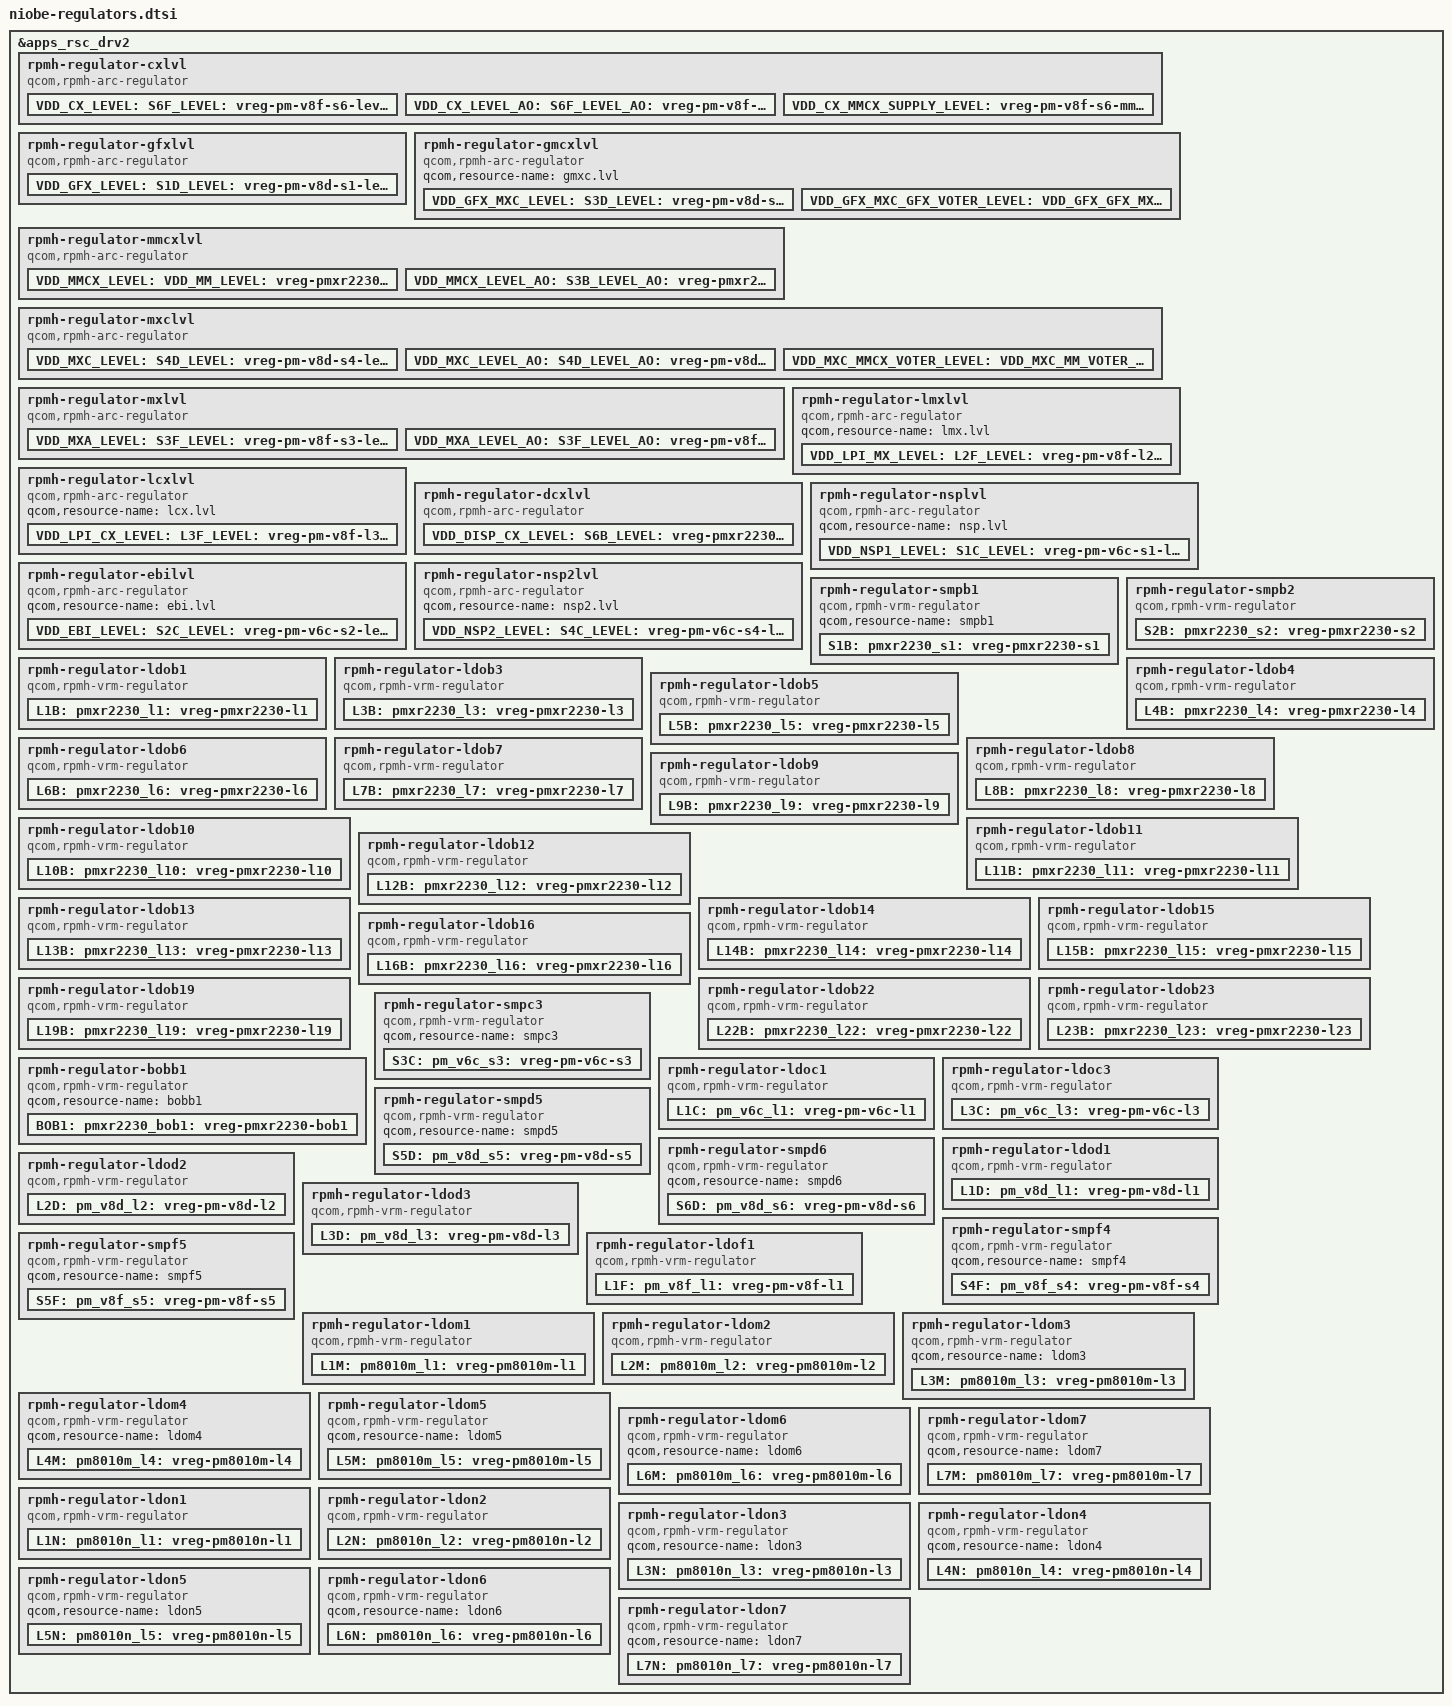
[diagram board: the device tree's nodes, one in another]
#include <dt-bindings/regulator/qcom,rpmh-regulator-levels.h>

&apps_rsc_drv2 {
	rpmh-regulator-cxlvl {
		compatible = "qcom,rpmh-arc-regulator";
		qcom,resource-name = "cx.lvl";
		proxy-supply = <&VDD_CX_LEVEL>;

		VDD_CX_LEVEL:
		S6F_LEVEL:
		pm_v8f_s6_level: vreg-pm-v8f-s6-level {
			regulator-name = "pm_v8f_s6_level";
			qcom,set = <RPMH_REGULATOR_SET_ALL>;
			regulator-min-microvolt =
				<RPMH_REGULATOR_LEVEL_RETENTION>;
			regulator-max-microvolt = <RPMH_REGULATOR_LEVEL_MAX>;
			qcom,init-voltage-level =
				<RPMH_REGULATOR_LEVEL_TURBO>;
			qcom,proxy-consumer-enable;
			qcom,proxy-consumer-voltage =
				<RPMH_REGULATOR_LEVEL_TURBO
				 RPMH_REGULATOR_LEVEL_MAX>;
		};

		VDD_CX_LEVEL_AO:
		S6F_LEVEL_AO:
		pm_v8f_s6_level_ao: vreg-pm-v8f-s6-level-ao {
			regulator-name = "pm_v8f_s6_level_ao";
			qcom,set = <RPMH_REGULATOR_SET_ACTIVE>;
			regulator-min-microvolt =
				<RPMH_REGULATOR_LEVEL_RETENTION>;
			regulator-max-microvolt = <RPMH_REGULATOR_LEVEL_MAX>;
			qcom,init-voltage-level =
				<RPMH_REGULATOR_LEVEL_RETENTION>;
		};

		VDD_CX_MMCX_SUPPLY_LEVEL: vreg-pm-v8f-s6-mmcx-sup-level {
			regulator-name = "pm_v8f_s6_mmcx_sup_level";
			qcom,set = <RPMH_REGULATOR_SET_ALL>;
			regulator-min-microvolt =
				<RPMH_REGULATOR_LEVEL_MIN_SVS>;
			regulator-max-microvolt =
				<RPMH_REGULATOR_LEVEL_MAX>;
			qcom,init-voltage-level =
				<RPMH_REGULATOR_LEVEL_MIN_SVS>;
		};
	};

	rpmh-regulator-gfxlvl {
		compatible = "qcom,rpmh-arc-regulator";
		qcom,resource-name = "gfx.lvl";
		proxy-supply = <&VDD_GFX_LEVEL>;

		VDD_GFX_LEVEL:
		S1D_LEVEL:
		pm_v8d_s1_level: vreg-pm-v8d-s1-level {
			regulator-name = "pm_v8d_s1_level";
			qcom,set = <RPMH_REGULATOR_SET_ALL>;
			regulator-min-microvolt =
				<RPMH_REGULATOR_LEVEL_RETENTION>;
			regulator-max-microvolt = <RPMH_REGULATOR_LEVEL_MAX>;
			qcom,init-voltage-level =
				<RPMH_REGULATOR_LEVEL_RETENTION>;
			qcom,proxy-consumer-enable;
			qcom,proxy-consumer-voltage =
				<RPMH_REGULATOR_LEVEL_LOW_SVS
				 RPMH_REGULATOR_LEVEL_MAX>;
		};
	};

	rpmh-regulator-gmcxlvl {
		compatible = "qcom,rpmh-arc-regulator";
		qcom,resource-name = "gmxc.lvl";

		VDD_GFX_MXC_LEVEL:
		S3D_LEVEL:
		pm_v8d_s3_level: vreg-pm-v8d-s3-level {
			regulator-name = "pm_v8d_s3_level";
			qcom,set = <RPMH_REGULATOR_SET_ALL>;
			regulator-min-microvolt =
				<RPMH_REGULATOR_LEVEL_RETENTION>;
			regulator-max-microvolt = <RPMH_REGULATOR_LEVEL_MAX>;
			qcom,init-voltage-level =
				<RPMH_REGULATOR_LEVEL_RETENTION>;
		};

		VDD_GFX_MXC_GFX_VOTER_LEVEL: VDD_GFX_GFX_MXC_VOTER_LEVEL:
		vreg-pm-v8d-s3-gfx-voter-level {
			regulator-name = "pm_v8d_s3_gfx_voter_level";
			pm_v8d_s3_gfx_voter_level-parent-supply =
				<&VDD_GFX_LEVEL>;
			qcom,set = <RPMH_REGULATOR_SET_ALL>;
			regulator-min-microvolt =
				<RPMH_REGULATOR_LEVEL_MIN_SVS>;
			regulator-max-microvolt =
				<RPMH_REGULATOR_LEVEL_MAX>;
			qcom,init-voltage-level =
				<RPMH_REGULATOR_LEVEL_MIN_SVS>;
		};
	};

	rpmh-regulator-mmcxlvl {
		compatible = "qcom,rpmh-arc-regulator";
		qcom,resource-name = "mmcx.lvl";
		proxy-supply = <&VDD_MMCX_LEVEL>;

		VDD_MMCX_LEVEL:
		VDD_MM_LEVEL:
		S3B_LEVEL:
		pmxr2230_s3_level: vreg-pmxr2230-s3-level {
			regulator-name = "pmxr2230_s3_level";
			qcom,set = <RPMH_REGULATOR_SET_ALL>;
			pmxr2230_s3_level-parent-supply =
				<&VDD_CX_MMCX_SUPPLY_LEVEL>;
			regulator-min-microvolt =
				<RPMH_REGULATOR_LEVEL_LOW_SVS_D1>;
			regulator-max-microvolt = <RPMH_REGULATOR_LEVEL_MAX>;
			qcom,init-voltage-level =
				<RPMH_REGULATOR_LEVEL_TURBO>;
			qcom,proxy-consumer-enable;
			qcom,proxy-consumer-voltage =
				<RPMH_REGULATOR_LEVEL_TURBO
				 RPMH_REGULATOR_LEVEL_MAX>;
		};

		VDD_MMCX_LEVEL_AO:
		S3B_LEVEL_AO:
		pmxr2230_s3_level_ao: vreg-pmxr2230-s3-level-ao {
			regulator-name = "pmxr2230_s3_level_ao";
			qcom,set = <RPMH_REGULATOR_SET_ACTIVE>;
			regulator-min-microvolt =
				<RPMH_REGULATOR_LEVEL_LOW_SVS_D1>;
			regulator-max-microvolt = <RPMH_REGULATOR_LEVEL_MAX>;
			qcom,init-voltage-level =
				<RPMH_REGULATOR_LEVEL_LOW_SVS_D1>;
		};
	};

	rpmh-regulator-mxclvl {
		compatible = "qcom,rpmh-arc-regulator";
		qcom,resource-name = "mxc.lvl";
		proxy-supply = <&VDD_MXC_LEVEL>;

		VDD_MXC_LEVEL:
		S4D_LEVEL:
		pm_v8d_s4_level: vreg-pm-v8d-s4-level {
			regulator-name = "pm_v8d_s4_level";
			qcom,set = <RPMH_REGULATOR_SET_ALL>;
			regulator-min-microvolt =
				<RPMH_REGULATOR_LEVEL_RETENTION>;
			regulator-max-microvolt = <RPMH_REGULATOR_LEVEL_MAX>;
			qcom,init-voltage-level =
				<RPMH_REGULATOR_LEVEL_TURBO>;
			qcom,proxy-consumer-enable;
			qcom,proxy-consumer-voltage =
				<RPMH_REGULATOR_LEVEL_TURBO
				 RPMH_REGULATOR_LEVEL_MAX>;
		};

		VDD_MXC_LEVEL_AO:
		S4D_LEVEL_AO:
		pm_v8d_s4_level_ao: vreg-pm-v8d-s4-level-ao {
			regulator-name = "pm_v8d_s4_level_ao";
			qcom,set = <RPMH_REGULATOR_SET_ACTIVE>;
			regulator-min-microvolt =
				<RPMH_REGULATOR_LEVEL_RETENTION>;
			regulator-max-microvolt = <RPMH_REGULATOR_LEVEL_MAX>;
			qcom,init-voltage-level =
				<RPMH_REGULATOR_LEVEL_RETENTION>;
		};

		VDD_MXC_MMCX_VOTER_LEVEL: VDD_MXC_MM_VOTER_LEVEL:
		VDD_MM_MXC_VOTER_LEVEL:
		vreg-pm-v8d-s4-mmcx-voter-level {
			regulator-name = "pm_v8d_s4_mmcx_voter_level";
			pm_v8d_s4_mmcx_voter_level-parent-supply =
				<&VDD_MMCX_LEVEL>;
			qcom,set = <RPMH_REGULATOR_SET_ALL>;
			regulator-min-microvolt =
				<RPMH_REGULATOR_LEVEL_MIN_SVS>;
			regulator-max-microvolt =
				<RPMH_REGULATOR_LEVEL_MAX>;
			qcom,init-voltage-level =
				<RPMH_REGULATOR_LEVEL_MIN_SVS>;
		};
	};

	rpmh-regulator-mxlvl {
		compatible = "qcom,rpmh-arc-regulator";
		qcom,resource-name = "mx.lvl";
		proxy-supply = <&VDD_MXA_LEVEL>;

		VDD_MXA_LEVEL:
		S3F_LEVEL:
		pm_v8f_s3_level: vreg-pm-v8f-s3-level {
			regulator-name = "pm_v8f_s3_level";
			qcom,set = <RPMH_REGULATOR_SET_ALL>;
			regulator-min-microvolt =
				<RPMH_REGULATOR_LEVEL_RETENTION>;
			regulator-max-microvolt = <RPMH_REGULATOR_LEVEL_MAX>;
			qcom,init-voltage-level =
				<RPMH_REGULATOR_LEVEL_TURBO>;
			qcom,proxy-consumer-enable;
			qcom,proxy-consumer-voltage =
				<RPMH_REGULATOR_LEVEL_TURBO
				 RPMH_REGULATOR_LEVEL_MAX>;
		};

		VDD_MXA_LEVEL_AO:
		S3F_LEVEL_AO:
		pm_v8f_s3_level_ao: vreg-pm-v8f-s3-level-ao {
			regulator-name = "pm_v8f_s3_level_ao";
			qcom,set = <RPMH_REGULATOR_SET_ACTIVE>;
			regulator-min-microvolt =
				<RPMH_REGULATOR_LEVEL_RETENTION>;
			regulator-max-microvolt = <RPMH_REGULATOR_LEVEL_MAX>;
			qcom,init-voltage-level =
				<RPMH_REGULATOR_LEVEL_RETENTION>;
		};
	};

	rpmh-regulator-lmxlvl {
		compatible = "qcom,rpmh-arc-regulator";
		qcom,resource-name = "lmx.lvl";

		VDD_LPI_MX_LEVEL:
		L2F_LEVEL:
		pm_v8f_l2_level: vreg-pm-v8f-l2-level {
			regulator-name = "pm_v8f_l2_level";
			qcom,set = <RPMH_REGULATOR_SET_ALL>;
			regulator-min-microvolt =
				<RPMH_REGULATOR_LEVEL_RETENTION>;
			regulator-max-microvolt = <RPMH_REGULATOR_LEVEL_MAX>;
			qcom,init-voltage-level =
				<RPMH_REGULATOR_LEVEL_RETENTION>;
		};
	};

	rpmh-regulator-lcxlvl {
		compatible = "qcom,rpmh-arc-regulator";
		qcom,resource-name = "lcx.lvl";

		VDD_LPI_CX_LEVEL:
		L3F_LEVEL:
		pm_v8f_l3_level: vreg-pm-v8f-l3-level {
			regulator-name = "pm_v8f_l3_level";
			qcom,set = <RPMH_REGULATOR_SET_ALL>;
			regulator-min-microvolt =
				<RPMH_REGULATOR_LEVEL_RETENTION>;
			regulator-max-microvolt = <RPMH_REGULATOR_LEVEL_MAX>;
			qcom,init-voltage-level =
				<RPMH_REGULATOR_LEVEL_RETENTION>;
		};
	};

	rpmh-regulator-dcxlvl {
		compatible = "qcom,rpmh-arc-regulator";
		qcom,resource-name = "dcx.lvl";
		proxy-supply = <&VDD_DISP_CX_LEVEL>;

		VDD_DISP_CX_LEVEL:
		S6B_LEVEL:
		pmxr2230_s6_level: vreg-pmxr2230-s6-level {
			regulator-name = "pmxr2230_s6_level";
			qcom,set = <RPMH_REGULATOR_SET_ALL>;
			regulator-min-microvolt =
				<RPMH_REGULATOR_LEVEL_LOW_SVS_D1>;
			regulator-max-microvolt = <RPMH_REGULATOR_LEVEL_MAX>;
			qcom,init-voltage-level =
				<RPMH_REGULATOR_LEVEL_LOW_SVS_D1>;
			qcom,proxy-consumer-enable;
			qcom,proxy-consumer-voltage =
				<RPMH_REGULATOR_LEVEL_TURBO
				 RPMH_REGULATOR_LEVEL_MAX>;
		};
	};

	rpmh-regulator-nsplvl {
		compatible = "qcom,rpmh-arc-regulator";
		qcom,resource-name = "nsp.lvl";

		VDD_NSP1_LEVEL:
		S1C_LEVEL:
		pm_v6c_s1_level: vreg-pm-v6c-s1-level {
			regulator-name = "pm_v6c_s1_level";
			qcom,set = <RPMH_REGULATOR_SET_ALL>;
			regulator-min-microvolt =
				<RPMH_REGULATOR_LEVEL_RETENTION>;
			regulator-max-microvolt = <RPMH_REGULATOR_LEVEL_MAX>;
			qcom,init-voltage-level =
				<RPMH_REGULATOR_LEVEL_RETENTION>;
		};
	};

	rpmh-regulator-ebilvl {
		compatible = "qcom,rpmh-arc-regulator";
		qcom,resource-name = "ebi.lvl";

		VDD_EBI_LEVEL:
		S2C_LEVEL:
		pm_v6c_s2_level: vreg-pm-v6c-s2-level {
			regulator-name = "pm_v6c_s2_level";
			qcom,set = <RPMH_REGULATOR_SET_ALL>;
			regulator-min-microvolt =
				<RPMH_REGULATOR_LEVEL_RETENTION>;
			regulator-max-microvolt = <RPMH_REGULATOR_LEVEL_MAX>;
			qcom,init-voltage-level =
				<RPMH_REGULATOR_LEVEL_RETENTION>;
		};
	};

	rpmh-regulator-nsp2lvl {
		compatible = "qcom,rpmh-arc-regulator";
		qcom,resource-name = "nsp2.lvl";

		VDD_NSP2_LEVEL:
		S4C_LEVEL:
		pm_v6c_s4_level: vreg-pm-v6c-s4-level {
			regulator-name = "pm_v6c_s4_level";
			qcom,set = <RPMH_REGULATOR_SET_ALL>;
			regulator-min-microvolt =
				<RPMH_REGULATOR_LEVEL_RETENTION>;
			regulator-max-microvolt = <RPMH_REGULATOR_LEVEL_MAX>;
			qcom,init-voltage-level =
				<RPMH_REGULATOR_LEVEL_RETENTION>;
		};
	};

	rpmh-regulator-smpb1 {
		compatible = "qcom,rpmh-vrm-regulator";
		qcom,resource-name = "smpb1";

		S1B:
		pmxr2230_s1: vreg-pmxr2230-s1 {
			regulator-name = "pmxr2230_s1";
			qcom,set = <RPMH_REGULATOR_SET_ALL>;
			regulator-min-microvolt = <1856000>;
			regulator-max-microvolt = <2040000>;
			qcom,init-voltage = <1856000>;
		};
	};

	rpmh-regulator-smpb2 {
		compatible = "qcom,rpmh-vrm-regulator";
		qcom,resource-name = "smpb2";
		qcom,regulator-type = "pmic5-ftsmps";
		qcom,supported-modes =
			<RPMH_REGULATOR_MODE_RET
			RPMH_REGULATOR_MODE_HPM>;
		qcom,mode-threshold-currents = <0 200000>;

		S2B:
		pmxr2230_s2: vreg-pmxr2230-s2 {
			regulator-name = "pmxr2230_s2";
			qcom,set = <RPMH_REGULATOR_SET_ALL>;
			regulator-min-microvolt = <1216000>;
			regulator-max-microvolt = <1408000>;
			qcom,init-voltage = <1256000>;
			qcom,init-mode = <RPMH_REGULATOR_MODE_RET>;
		};
	};

	rpmh-regulator-ldob1 {
		compatible = "qcom,rpmh-vrm-regulator";
		qcom,resource-name = "ldob1";
		qcom,regulator-type = "pmic5-ldo";
		qcom,supported-modes =
			<RPMH_REGULATOR_MODE_LPM
			RPMH_REGULATOR_MODE_HPM>;
		qcom,mode-threshold-currents = <0 30000>;

		L1B:
		pmxr2230_l1: vreg-pmxr2230-l1 {
			regulator-name = "pmxr2230_l1";
			qcom,set = <RPMH_REGULATOR_SET_ALL>;
			regulator-min-microvolt = <880000>;
			regulator-max-microvolt = <912000>;
			qcom,init-voltage = <880000>;
			qcom,init-mode = <RPMH_REGULATOR_MODE_HPM>;
		};
	};

	rpmh-regulator-ldob3 {
		compatible = "qcom,rpmh-vrm-regulator";
		qcom,resource-name = "ldob3";
		qcom,regulator-type = "pmic5-ldo";
		qcom,supported-modes =
			<RPMH_REGULATOR_MODE_RET
			RPMH_REGULATOR_MODE_LPM
			RPMH_REGULATOR_MODE_HPM>;
		qcom,mode-threshold-currents = <0 10000 30000>;

		L3B:
		pmxr2230_l3: vreg-pmxr2230-l3 {
			regulator-name = "pmxr2230_l3";
			qcom,set = <RPMH_REGULATOR_SET_ALL>;
			regulator-min-microvolt = <1200000>;
			regulator-max-microvolt = <1200000>;
			qcom,init-voltage = <1200000>;
			qcom,init-mode = <RPMH_REGULATOR_MODE_HPM>;
		};
	};

	rpmh-regulator-ldob4 {
		compatible = "qcom,rpmh-vrm-regulator";
		qcom,resource-name = "ldob4";
		qcom,regulator-type = "pmic5-ldo";
		qcom,supported-modes =
			<RPMH_REGULATOR_MODE_LPM
			RPMH_REGULATOR_MODE_HPM>;
		qcom,mode-threshold-currents = <0 30000>;

		L4B:
		pmxr2230_l4: vreg-pmxr2230-l4 {
			regulator-name = "pmxr2230_l4";
			qcom,set = <RPMH_REGULATOR_SET_ALL>;
			regulator-min-microvolt = <1800000>;
			regulator-max-microvolt = <1800000>;
			qcom,init-voltage = <1800000>;
			qcom,init-mode = <RPMH_REGULATOR_MODE_HPM>;
		};
	};

	rpmh-regulator-ldob5 {
		compatible = "qcom,rpmh-vrm-regulator";
		qcom,resource-name = "ldob5";
		qcom,regulator-type = "pmic5-ldo";
		qcom,supported-modes =
			<RPMH_REGULATOR_MODE_LPM
			RPMH_REGULATOR_MODE_HPM>;
		qcom,mode-threshold-currents = <0 30000>;

		L5B:
		pmxr2230_l5: vreg-pmxr2230-l5 {
			regulator-name = "pmxr2230_l5";
			qcom,set = <RPMH_REGULATOR_SET_ALL>;
			regulator-min-microvolt = <1800000>;
			regulator-max-microvolt = <1800000>;
			qcom,init-voltage = <1800000>;
			qcom,init-mode = <RPMH_REGULATOR_MODE_HPM>;
		};
	};

	rpmh-regulator-ldob6 {
		compatible = "qcom,rpmh-vrm-regulator";
		qcom,resource-name = "ldob6";
		qcom,regulator-type = "pmic5-ldo";
		qcom,supported-modes =
			<RPMH_REGULATOR_MODE_LPM
			RPMH_REGULATOR_MODE_HPM>;
		qcom,mode-threshold-currents = <0 30000>;

		L6B:
		pmxr2230_l6: vreg-pmxr2230-l6 {
			regulator-name = "pmxr2230_l6";
			qcom,set = <RPMH_REGULATOR_SET_ALL>;
			regulator-min-microvolt = <1800000>;
			regulator-max-microvolt = <1800000>;
			qcom,init-voltage = <1800000>;
			qcom,init-mode = <RPMH_REGULATOR_MODE_HPM>;
		};
	};

	rpmh-regulator-ldob7 {
		compatible = "qcom,rpmh-vrm-regulator";
		qcom,resource-name = "ldob7";
		qcom,regulator-type = "pmic5-ldo";
		qcom,supported-modes =
			<RPMH_REGULATOR_MODE_LPM
			RPMH_REGULATOR_MODE_HPM>;
		qcom,mode-threshold-currents = <0 30000>;

		L7B:
		pmxr2230_l7: vreg-pmxr2230-l7 {
			regulator-name = "pmxr2230_l7";
			qcom,set = <RPMH_REGULATOR_SET_ALL>;
			regulator-min-microvolt = <1800000>;
			regulator-max-microvolt = <1800000>;
			qcom,init-voltage = <1800000>;
			qcom,init-mode = <RPMH_REGULATOR_MODE_HPM>;
		};
	};

	rpmh-regulator-ldob8 {
		compatible = "qcom,rpmh-vrm-regulator";
		qcom,resource-name = "ldob8";
		qcom,regulator-type = "pmic5-ldo";
		qcom,supported-modes =
			<RPMH_REGULATOR_MODE_LPM
			RPMH_REGULATOR_MODE_HPM>;
		qcom,mode-threshold-currents = <0 30000>;

		L8B:
		pmxr2230_l8: vreg-pmxr2230-l8 {
			regulator-name = "pmxr2230_l8";
			qcom,set = <RPMH_REGULATOR_SET_ALL>;
			regulator-min-microvolt = <880000>;
			regulator-max-microvolt = <880000>;
			qcom,init-voltage = <880000>;
			qcom,init-mode = <RPMH_REGULATOR_MODE_HPM>;
		};
	};

	rpmh-regulator-ldob9 {
		compatible = "qcom,rpmh-vrm-regulator";
		qcom,resource-name = "ldob9";
		qcom,regulator-type = "pmic5-ldo";
		qcom,supported-modes =
			<RPMH_REGULATOR_MODE_LPM
			RPMH_REGULATOR_MODE_HPM>;
		qcom,mode-threshold-currents = <0 30000>;

		L9B:
		pmxr2230_l9: vreg-pmxr2230-l9 {
			regulator-name = "pmxr2230_l9";
			qcom,set = <RPMH_REGULATOR_SET_ALL>;
			regulator-min-microvolt = <880000>;
			regulator-max-microvolt = <880000>;
			qcom,init-voltage = <880000>;
			qcom,init-mode = <RPMH_REGULATOR_MODE_HPM>;
		};
	};

	rpmh-regulator-ldob10 {
		compatible = "qcom,rpmh-vrm-regulator";
		qcom,resource-name = "ldob10";
		qcom,regulator-type = "pmic5-ldo";
		qcom,supported-modes =
			<RPMH_REGULATOR_MODE_LPM
			RPMH_REGULATOR_MODE_HPM>;
		qcom,mode-threshold-currents = <0 30000>;

		L10B:
		pmxr2230_l10: vreg-pmxr2230-l10 {
			regulator-name = "pmxr2230_l10";
			qcom,set = <RPMH_REGULATOR_SET_ALL>;
			regulator-min-microvolt = <880000>;
			regulator-max-microvolt = <880000>;
			qcom,init-voltage = <880000>;
			qcom,init-mode = <RPMH_REGULATOR_MODE_HPM>;
		};
	};

	rpmh-regulator-ldob11 {
		compatible = "qcom,rpmh-vrm-regulator";
		qcom,resource-name = "ldob11";
		qcom,regulator-type = "pmic5-ldo";
		qcom,supported-modes =
			<RPMH_REGULATOR_MODE_LPM
			RPMH_REGULATOR_MODE_HPM>;
		qcom,mode-threshold-currents = <0 30000>;

		L11B:
		pmxr2230_l11: vreg-pmxr2230-l11 {
			regulator-name = "pmxr2230_l11";
			qcom,set = <RPMH_REGULATOR_SET_ALL>;
			regulator-min-microvolt = <1800000>;
			regulator-max-microvolt = <1800000>;
			qcom,init-voltage = <1800000>;
			qcom,init-mode = <RPMH_REGULATOR_MODE_HPM>;
		};
	};

	rpmh-regulator-ldob12 {
		compatible = "qcom,rpmh-vrm-regulator";
		qcom,resource-name = "ldob12";
		qcom,regulator-type = "pmic5-ldo";
		qcom,supported-modes =
			<RPMH_REGULATOR_MODE_LPM
			RPMH_REGULATOR_MODE_HPM>;
		qcom,mode-threshold-currents = <0 10000>;

		L12B:
		pmxr2230_l12: vreg-pmxr2230-l12 {
			regulator-name = "pmxr2230_l12";
			qcom,set = <RPMH_REGULATOR_SET_ALL>;
			regulator-min-microvolt = <2700000>;
			regulator-max-microvolt = <3304000>;
			qcom,init-voltage = <2700000>;
			qcom,init-mode = <RPMH_REGULATOR_MODE_HPM>;
		};
	};

	rpmh-regulator-ldob13 {
		compatible = "qcom,rpmh-vrm-regulator";
		qcom,resource-name = "ldob13";
		qcom,regulator-type = "pmic5-ldo";
		qcom,supported-modes =
			<RPMH_REGULATOR_MODE_LPM
			RPMH_REGULATOR_MODE_HPM>;
		qcom,mode-threshold-currents = <0 10000>;

		L13B:
		pmxr2230_l13: vreg-pmxr2230-l13 {
			regulator-name = "pmxr2230_l13";
			qcom,set = <RPMH_REGULATOR_SET_ALL>;
			regulator-min-microvolt = <2504000>;
			regulator-max-microvolt = <2800000>;
			qcom,init-voltage = <2504000>;
			qcom,init-mode = <RPMH_REGULATOR_MODE_HPM>;
		};
	};

	rpmh-regulator-ldob14 {
		compatible = "qcom,rpmh-vrm-regulator";
		qcom,resource-name = "ldob14";
		qcom,regulator-type = "pmic5-ldo";
		qcom,supported-modes =
			<RPMH_REGULATOR_MODE_LPM
			RPMH_REGULATOR_MODE_HPM>;
		qcom,mode-threshold-currents = <0 10000>;

		L14B:
		pmxr2230_l14: vreg-pmxr2230-l14 {
			regulator-name = "pmxr2230_l14";
			qcom,set = <RPMH_REGULATOR_SET_ALL>;
			regulator-min-microvolt = <2504000>;
			regulator-max-microvolt = <3304000>;
			qcom,init-voltage = <2504000>;
			qcom,init-mode = <RPMH_REGULATOR_MODE_HPM>;
		};
	};

	rpmh-regulator-ldob15 {
		compatible = "qcom,rpmh-vrm-regulator";
		qcom,resource-name = "ldob15";
		qcom,regulator-type = "pmic5-ldo";
		qcom,supported-modes =
			<RPMH_REGULATOR_MODE_LPM
			RPMH_REGULATOR_MODE_HPM>;
		qcom,mode-threshold-currents = <0 10000>;

		L15B:
		pmxr2230_l15: vreg-pmxr2230-l15 {
			regulator-name = "pmxr2230_l15";
			qcom,set = <RPMH_REGULATOR_SET_ALL>;
			regulator-min-microvolt = <2700000>;
			regulator-max-microvolt = <3304000>;
			qcom,init-voltage = <3104000>;
			qcom,init-mode = <RPMH_REGULATOR_MODE_HPM>;
		};
	};

	rpmh-regulator-ldob16 {
		compatible = "qcom,rpmh-vrm-regulator";
		qcom,resource-name = "ldob16";
		qcom,regulator-type = "pmic5-ldo";
		qcom,supported-modes =
			<RPMH_REGULATOR_MODE_LPM
			RPMH_REGULATOR_MODE_HPM>;
		qcom,mode-threshold-currents = <0 10000>;

		L16B:
		pmxr2230_l16: vreg-pmxr2230-l16 {
			regulator-name = "pmxr2230_l16";
			qcom,set = <RPMH_REGULATOR_SET_ALL>;
			regulator-min-microvolt = <3304000>;
			regulator-max-microvolt = <3304000>;
			qcom,init-voltage = <3304000>;
			qcom,init-mode = <RPMH_REGULATOR_MODE_HPM>;
		};
	};

	rpmh-regulator-ldob19 {
		compatible = "qcom,rpmh-vrm-regulator";
		qcom,resource-name = "ldob19";
		qcom,regulator-type = "pmic5-ldo";
		qcom,supported-modes =
			<RPMH_REGULATOR_MODE_LPM
			RPMH_REGULATOR_MODE_HPM>;
		qcom,mode-threshold-currents = <0 10000>;

		L19B:
		pmxr2230_l19: vreg-pmxr2230-l19 {
			regulator-name = "pmxr2230_l19";
			qcom,set = <RPMH_REGULATOR_SET_ALL>;
			regulator-min-microvolt = <1800000>;
			regulator-max-microvolt = <3304000>;
			qcom,init-voltage = <1800000>;
			qcom,init-mode = <RPMH_REGULATOR_MODE_HPM>;
		};
	};

	rpmh-regulator-ldob22 {
		compatible = "qcom,rpmh-vrm-regulator";
		qcom,resource-name = "ldob22";
		qcom,regulator-type = "pmic5-ldo";
		qcom,supported-modes =
			<RPMH_REGULATOR_MODE_LPM
			RPMH_REGULATOR_MODE_HPM>;
		qcom,mode-threshold-currents = <0 10000>;

		L22B:
		pmxr2230_l22: vreg-pmxr2230-l22 {
			regulator-name = "pmxr2230_l22";
			qcom,set = <RPMH_REGULATOR_SET_ALL>;
			regulator-min-microvolt = <2800000>;
			regulator-max-microvolt = <2800000>;
			qcom,init-voltage = <2800000>;
			qcom,init-mode = <RPMH_REGULATOR_MODE_HPM>;
		};
	};

	rpmh-regulator-ldob23 {
		compatible = "qcom,rpmh-vrm-regulator";
		qcom,resource-name = "ldob23";
		qcom,regulator-type = "pmic5-ldo";
		qcom,supported-modes =
			<RPMH_REGULATOR_MODE_LPM
			RPMH_REGULATOR_MODE_HPM>;
		qcom,mode-threshold-currents = <0 10000>;

		L23B:
		pmxr2230_l23: vreg-pmxr2230-l23 {
			regulator-name = "pmxr2230_l23";
			qcom,set = <RPMH_REGULATOR_SET_ALL>;
			regulator-min-microvolt = <2800000>;
			regulator-max-microvolt = <2800000>;
			qcom,init-voltage = <2800000>;
			qcom,init-mode = <RPMH_REGULATOR_MODE_HPM>;
		};
	};

	rpmh-regulator-bobb1 {
		compatible = "qcom,rpmh-vrm-regulator";
		qcom,resource-name = "bobb1";

		BOB1: pmxr2230_bob1: vreg-pmxr2230-bob1 {
			regulator-name = "pmxr2230_bob1";
			qcom,set = <RPMH_REGULATOR_SET_ALL>;
			regulator-min-microvolt = <3008000>;
			regulator-max-microvolt = <3960000>;
			qcom,init-voltage = <3296000>;
		};
	};

	rpmh-regulator-smpc3 {
		compatible = "qcom,rpmh-vrm-regulator";
		qcom,resource-name = "smpc3";

		S3C:
		pm_v6c_s3: vreg-pm-v6c-s3 {
			regulator-name = "pm_v6c_s3";
			qcom,set = <RPMH_REGULATOR_SET_ALL>;
			regulator-min-microvolt = <300000>;
			regulator-max-microvolt = <570000>;
			qcom,init-voltage = <504000>;
		};
	};

	rpmh-regulator-ldoc1 {
		compatible = "qcom,rpmh-vrm-regulator";
		qcom,resource-name = "ldoc1";
		qcom,regulator-type = "pmic5-ldo";
		qcom,supported-modes =
			<RPMH_REGULATOR_MODE_LPM
			RPMH_REGULATOR_MODE_HPM>;
		qcom,mode-threshold-currents = <0 30000>;
		proxy-supply = <&L1C>;

		L1C:
		pm_v6c_l1: vreg-pm-v6c-l1 {
			regulator-name = "pm_v6c_l1";
			qcom,set = <RPMH_REGULATOR_SET_ALL>;
			qcom,init-mode = <RPMH_REGULATOR_MODE_HPM>;
			qcom,proxy-consumer-enable;
			qcom,proxy-consumer-current = <31000>;
		};
	};

	rpmh-regulator-ldoc3 {
		compatible = "qcom,rpmh-vrm-regulator";
		qcom,resource-name = "ldoc3";
		qcom,regulator-type = "pmic5-ldo";
		qcom,supported-modes =
			<RPMH_REGULATOR_MODE_LPM
			RPMH_REGULATOR_MODE_HPM>;
		qcom,mode-threshold-currents = <0 30000>;

		L3C:
		pm_v6c_l3: vreg-pm-v6c-l3 {
			regulator-name = "pm_v6c_l3";
			qcom,set = <RPMH_REGULATOR_SET_ALL>;
			regulator-min-microvolt = <880000>;
			regulator-max-microvolt = <912000>;
			qcom,init-voltage = <912000>;
			qcom,init-mode = <RPMH_REGULATOR_MODE_HPM>;
		};
	};

	rpmh-regulator-smpd5 {
		compatible = "qcom,rpmh-vrm-regulator";
		qcom,resource-name = "smpd5";

		S5D:
		pm_v8d_s5: vreg-pm-v8d-s5 {
			regulator-name = "pm_v8d_s5";
			qcom,set = <RPMH_REGULATOR_SET_ALL>;
			regulator-min-microvolt = <300000>;
			regulator-max-microvolt = <1004000>;
			qcom,init-voltage = <300000>;
		};
	};

	rpmh-regulator-smpd6 {
		compatible = "qcom,rpmh-vrm-regulator";
		qcom,resource-name = "smpd6";

		S6D:
		pm_v8d_s6: vreg-pm-v8d-s6 {
			regulator-name = "pm_v8d_s6";
			qcom,set = <RPMH_REGULATOR_SET_ALL>;
			regulator-min-microvolt = <880000>;
			regulator-max-microvolt = <1040000>;
			qcom,init-voltage = <976000>;
		};
	};

	rpmh-regulator-ldod1 {
		compatible = "qcom,rpmh-vrm-regulator";
		qcom,resource-name = "ldod1";
		qcom,regulator-type = "pmic5-ldo";
		qcom,supported-modes =
			<RPMH_REGULATOR_MODE_LPM
			RPMH_REGULATOR_MODE_HPM>;
		qcom,mode-threshold-currents = <0 30000>;

		L1D:
		pm_v8d_l1: vreg-pm-v8d-l1 {
			regulator-name = "pm_v8d_l1";
			qcom,set = <RPMH_REGULATOR_SET_ALL>;
			regulator-min-microvolt = <1200000>;
			regulator-max-microvolt = <1200000>;
			qcom,init-voltage = <1200000>;
			qcom,init-mode = <RPMH_REGULATOR_MODE_HPM>;
		};
	};

	rpmh-regulator-ldod2 {
		compatible = "qcom,rpmh-vrm-regulator";
		qcom,resource-name = "ldod2";
		qcom,regulator-type = "pmic5-ldo";
		qcom,supported-modes =
			<RPMH_REGULATOR_MODE_LPM
			RPMH_REGULATOR_MODE_HPM>;
		qcom,mode-threshold-currents = <0 30000>;

		L2D:
		pm_v8d_l2: vreg-pm-v8d-l2 {
			regulator-name = "pm_v8d_l2";
			qcom,set = <RPMH_REGULATOR_SET_ALL>;
			regulator-min-microvolt = <880000>;
			regulator-max-microvolt = <912000>;
			qcom,init-voltage = <880000>;
			qcom,init-mode = <RPMH_REGULATOR_MODE_HPM>;
		};
	};

	rpmh-regulator-ldod3 {
		compatible = "qcom,rpmh-vrm-regulator";
		qcom,resource-name = "ldod3";
		qcom,regulator-type = "pmic5-ldo";
		qcom,supported-modes =
			<RPMH_REGULATOR_MODE_LPM
			RPMH_REGULATOR_MODE_HPM>;
		qcom,mode-threshold-currents = <0 30000>;

		L3D:
		pm_v8d_l3: vreg-pm-v8d-l3 {
			regulator-name = "pm_v8d_l3";
			qcom,set = <RPMH_REGULATOR_SET_ALL>;
			regulator-min-microvolt = <880000>;
			regulator-max-microvolt = <912000>;
			qcom,init-voltage = <880000>;
			qcom,init-mode = <RPMH_REGULATOR_MODE_HPM>;
		};
	};

	rpmh-regulator-smpf4 {
		compatible = "qcom,rpmh-vrm-regulator";
		qcom,resource-name = "smpf4";

		S4F:
		pm_v8f_s4: vreg-pm-v8f-s4 {
			regulator-name = "pm_v8f_s4";
			qcom,set = <RPMH_REGULATOR_SET_ALL>;
			regulator-min-microvolt = <1080000>;
			regulator-max-microvolt = <1100000>;
			qcom,init-voltage = <1080000>;
		};
	};

	rpmh-regulator-smpf5 {
		compatible = "qcom,rpmh-vrm-regulator";
		qcom,resource-name = "smpf5";

		S5F:
		pm_v8f_s5: vreg-pm-v8f-s5 {
			regulator-name = "pm_v8f_s5";
			qcom,set = <RPMH_REGULATOR_SET_ALL>;
			regulator-min-microvolt = <904000>;
			regulator-max-microvolt = <904000>;
			qcom,init-voltage = <904000>;
		};
	};

	rpmh-regulator-ldof1 {
		compatible = "qcom,rpmh-vrm-regulator";
		qcom,resource-name = "ldof1";
		qcom,regulator-type = "pmic5-ldo";
		qcom,supported-modes =
			<RPMH_REGULATOR_MODE_LPM
			RPMH_REGULATOR_MODE_HPM>;
		qcom,mode-threshold-currents = <0 30000>;

		L1F:
		pm_v8f_l1: vreg-pm-v8f-l1 {
			regulator-name = "pm_v8f_l1";
			qcom,set = <RPMH_REGULATOR_SET_ALL>;
			regulator-min-microvolt = <880000>;
			regulator-max-microvolt = <912000>;
			qcom,init-voltage = <880000>;
			qcom,init-mode = <RPMH_REGULATOR_MODE_HPM>;
		};
	};

	rpmh-regulator-ldom1 {
		compatible = "qcom,rpmh-vrm-regulator";
		qcom,resource-name = "ldom1";
		qcom,regulator-type = "pmic5-ldo";
		qcom,supported-modes =
			<RPMH_REGULATOR_MODE_LPM
			RPMH_REGULATOR_MODE_HPM>;
		qcom,mode-threshold-currents = <0 30000>;

		L1M:
		pm8010m_l1: vreg-pm8010m-l1 {
			regulator-name = "pm8010m_l1";
			qcom,set = <RPMH_REGULATOR_SET_ALL>;
			regulator-min-microvolt = <1200000>;
			regulator-max-microvolt = <1200000>;
			qcom,init-voltage = <1200000>;
			qcom,init-mode = <RPMH_REGULATOR_MODE_HPM>;
		};
	};

	rpmh-regulator-ldom2 {
		compatible = "qcom,rpmh-vrm-regulator";
		qcom,resource-name = "ldom2";
		qcom,regulator-type = "pmic5-ldo";
		qcom,supported-modes =
			<RPMH_REGULATOR_MODE_LPM
			RPMH_REGULATOR_MODE_HPM>;
		qcom,mode-threshold-currents = <0 30000>;

		L2M:
		pm8010m_l2: vreg-pm8010m-l2 {
			regulator-name = "pm8010m_l2";
			qcom,set = <RPMH_REGULATOR_SET_ALL>;
			regulator-min-microvolt = <1104000>;
			regulator-max-microvolt = <1104000>;
			qcom,init-voltage = <1104000>;
			qcom,init-mode = <RPMH_REGULATOR_MODE_HPM>;
		};
	};

	rpmh-regulator-ldom3 {
		compatible = "qcom,rpmh-vrm-regulator";
		qcom,resource-name = "ldom3";

		L3M:
		pm8010m_l3: vreg-pm8010m-l3 {
			regulator-name = "pm8010m_l3";
			qcom,set = <RPMH_REGULATOR_SET_ALL>;
			regulator-min-microvolt = <2800000>;
			regulator-max-microvolt = <2800000>;
			qcom,init-voltage = <2800000>;
		};
	};

	rpmh-regulator-ldom4 {
		compatible = "qcom,rpmh-vrm-regulator";
		qcom,resource-name = "ldom4";

		L4M:
		pm8010m_l4: vreg-pm8010m-l4 {
			regulator-name = "pm8010m_l4";
			qcom,set = <RPMH_REGULATOR_SET_ALL>;
			regulator-min-microvolt = <2800000>;
			regulator-max-microvolt = <2800000>;
			qcom,init-voltage = <2800000>;
		};
	};

	rpmh-regulator-ldom5 {
		compatible = "qcom,rpmh-vrm-regulator";
		qcom,resource-name = "ldom5";

		L5M:
		pm8010m_l5: vreg-pm8010m-l5 {
			regulator-name = "pm8010m_l5";
			qcom,set = <RPMH_REGULATOR_SET_ALL>;
			regulator-min-microvolt = <2800000>;
			regulator-max-microvolt = <2800000>;
			qcom,init-voltage = <2800000>;
		};
	};

	rpmh-regulator-ldom6 {
		compatible = "qcom,rpmh-vrm-regulator";
		qcom,resource-name = "ldom6";

		L6M:
		pm8010m_l6: vreg-pm8010m-l6 {
			regulator-name = "pm8010m_l6";
			qcom,set = <RPMH_REGULATOR_SET_ALL>;
			regulator-min-microvolt = <2800000>;
			regulator-max-microvolt = <2800000>;
			qcom,init-voltage = <2800000>;
		};
	};

	rpmh-regulator-ldom7 {
		compatible = "qcom,rpmh-vrm-regulator";
		qcom,resource-name = "ldom7";

		L7M:
		pm8010m_l7: vreg-pm8010m-l7 {
			regulator-name = "pm8010m_l7";
			qcom,set = <RPMH_REGULATOR_SET_ALL>;
			regulator-min-microvolt = <2800000>;
			regulator-max-microvolt = <2800000>;
			qcom,init-voltage = <2800000>;
		};
	};

	rpmh-regulator-ldon1 {
		compatible = "qcom,rpmh-vrm-regulator";
		qcom,resource-name = "ldon1";
		qcom,regulator-type = "pmic5-ldo";
		qcom,supported-modes =
			<RPMH_REGULATOR_MODE_LPM
			RPMH_REGULATOR_MODE_HPM>;
		qcom,mode-threshold-currents = <0 30000>;

		L1N:
		pm8010n_l1: vreg-pm8010n-l1 {
			regulator-name = "pm8010n_l1";
			qcom,set = <RPMH_REGULATOR_SET_ALL>;
			regulator-min-microvolt = <1140000>;
			regulator-max-microvolt = <1260000>;
			qcom,init-voltage = <1140000>;
			qcom,init-mode = <RPMH_REGULATOR_MODE_HPM>;
		};
	};

	rpmh-regulator-ldon2 {
		compatible = "qcom,rpmh-vrm-regulator";
		qcom,resource-name = "ldon2";
		qcom,regulator-type = "pmic5-ldo";
		qcom,supported-modes =
			<RPMH_REGULATOR_MODE_LPM
			RPMH_REGULATOR_MODE_HPM>;
		qcom,mode-threshold-currents = <0 30000>;

		L2N:
		pm8010n_l2: vreg-pm8010n-l2 {
			regulator-name = "pm8010n_l2";
			qcom,set = <RPMH_REGULATOR_SET_ALL>;
			regulator-min-microvolt = <1104000>;
			regulator-max-microvolt = <1104000>;
			qcom,init-voltage = <1104000>;
			qcom,init-mode = <RPMH_REGULATOR_MODE_HPM>;
		};
	};

	rpmh-regulator-ldon3 {
		compatible = "qcom,rpmh-vrm-regulator";
		qcom,resource-name = "ldon3";

		L3N:
		pm8010n_l3: vreg-pm8010n-l3 {
			regulator-name = "pm8010n_l3";
			qcom,set = <RPMH_REGULATOR_SET_ALL>;
			regulator-min-microvolt = <2800000>;
			regulator-max-microvolt = <2800000>;
			qcom,init-voltage = <2800000>;
		};
	};

	rpmh-regulator-ldon4 {
		compatible = "qcom,rpmh-vrm-regulator";
		qcom,resource-name = "ldon4";

		L4N:
		pm8010n_l4: vreg-pm8010n-l4 {
			regulator-name = "pm8010n_l4";
			qcom,set = <RPMH_REGULATOR_SET_ALL>;
			regulator-min-microvolt = <2800000>;
			regulator-max-microvolt = <2800000>;
			qcom,init-voltage = <2800000>;
		};
	};

	rpmh-regulator-ldon5 {
		compatible = "qcom,rpmh-vrm-regulator";
		qcom,resource-name = "ldon5";

		L5N:
		pm8010n_l5: vreg-pm8010n-l5 {
			regulator-name = "pm8010n_l5";
			qcom,set = <RPMH_REGULATOR_SET_ALL>;
			regulator-min-microvolt = <2800000>;
			regulator-max-microvolt = <2800000>;
			qcom,init-voltage = <2800000>;
		};
	};

	rpmh-regulator-ldon6 {
		compatible = "qcom,rpmh-vrm-regulator";
		qcom,resource-name = "ldon6";

		L6N:
		pm8010n_l6: vreg-pm8010n-l6 {
			regulator-name = "pm8010n_l6";
			qcom,set = <RPMH_REGULATOR_SET_ALL>;
			regulator-min-microvolt = <2960000>;
			regulator-max-microvolt = <2960000>;
			qcom,init-voltage = <2960000>;
		};
	};

	rpmh-regulator-ldon7 {
		compatible = "qcom,rpmh-vrm-regulator";
		qcom,resource-name = "ldon7";

		L7N:
		pm8010n_l7: vreg-pm8010n-l7 {
			regulator-name = "pm8010n_l7";
			qcom,set = <RPMH_REGULATOR_SET_ALL>;
			regulator-min-microvolt = <2800000>;
			regulator-max-microvolt = <2800000>;
			qcom,init-voltage = <2800000>;
		};
	};
};
